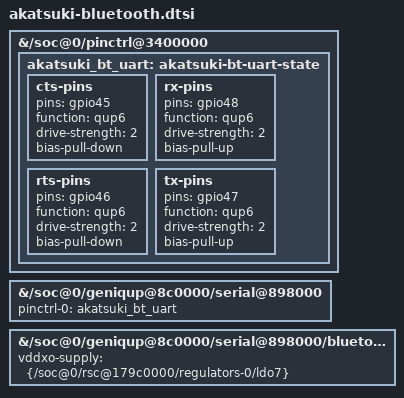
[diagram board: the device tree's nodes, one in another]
// SPDX-License-Identifier: GPL-2.0
/*
 * Bluetooth du Xperia XZ3 (WCN3990 sur l'UART 6).
 *
 * Liaison à 4 fils (TX, RX, CTS, RTS) comme chez Sony (qupv3_se6_4uart, GPIO 45
 * à 48) et sur les autres SDM845 (OnePlus 6, Pocophone F1). Le DTB mainline de
 * tama n'active que TX/RX : sans RTS, la puce répond au changement de débit avant
 * que l'hôte ait changé le sien, d'où « Frame reassembly failed (-84) » et
 * « Failed to change controller baudrate » (constaté le 12/10/2026).
 *
 * Polarisation des broches : TX (47) tiré vers le haut et RTS (46) tiré vers le
 * bas comme chez Sony ; CTS (45) tiré vers le bas et RX (48) vers le haut comme
 * dans sdm845.dtsi. Avec CTS libre (réglage Sony), le WCN3990 démarre et reçoit
 * son firmware, mais la première commande suivante échoue (0xfc14 tx timeout).
 * Hypothèse : en veille profonde la puce lâche sa ligne RTS, notre CTS flotte et bloque
 * l'émission de l'octet de réveil (le pilote Sony gère ce cas à part, pas le
 * mainline). Le tirage vers le bas garde CTS actif pendant la veille.
 *
 * Alimentations (relevé Sony : io S3A, xtal S5A, core L7A 1,8 V, pa L17A,
 * ldo L25A) : le pilote mainline n'a que vddio/vddxo/vddrf/vddch0. Le DTB tama
 * met vddxo sur S5A, qui n'est que la source de L7A ; les autres SDM845 mettent
 * L7A (1,8 V, aussi l'oscillateur du Wi-Fi). On fait de même : L7A tenue par le
 * Bluetooth garde S5A allumée.
 */
&{/soc@0/pinctrl@3400000} {
	akatsuki_bt_uart: akatsuki-bt-uart-state {
		cts-pins {
			pins = "gpio45";
			function = "qup6";
			drive-strength = <2>;
			bias-pull-down;
		};

		rx-pins {
			pins = "gpio48";
			function = "qup6";
			drive-strength = <2>;
			bias-pull-up;
		};

		rts-pins {
			pins = "gpio46";
			function = "qup6";
			drive-strength = <2>;
			bias-pull-down;
		};

		tx-pins {
			pins = "gpio47";
			function = "qup6";
			drive-strength = <2>;
			bias-pull-up;
		};
	};
};

&{/soc@0/geniqup@8c0000/serial@898000} {
	pinctrl-0 = <&akatsuki_bt_uart>;
};

&{/soc@0/geniqup@8c0000/serial@898000/bluetooth} {
	vddxo-supply = <&{/soc@0/rsc@179c0000/regulators-0/ldo7}>;
};
